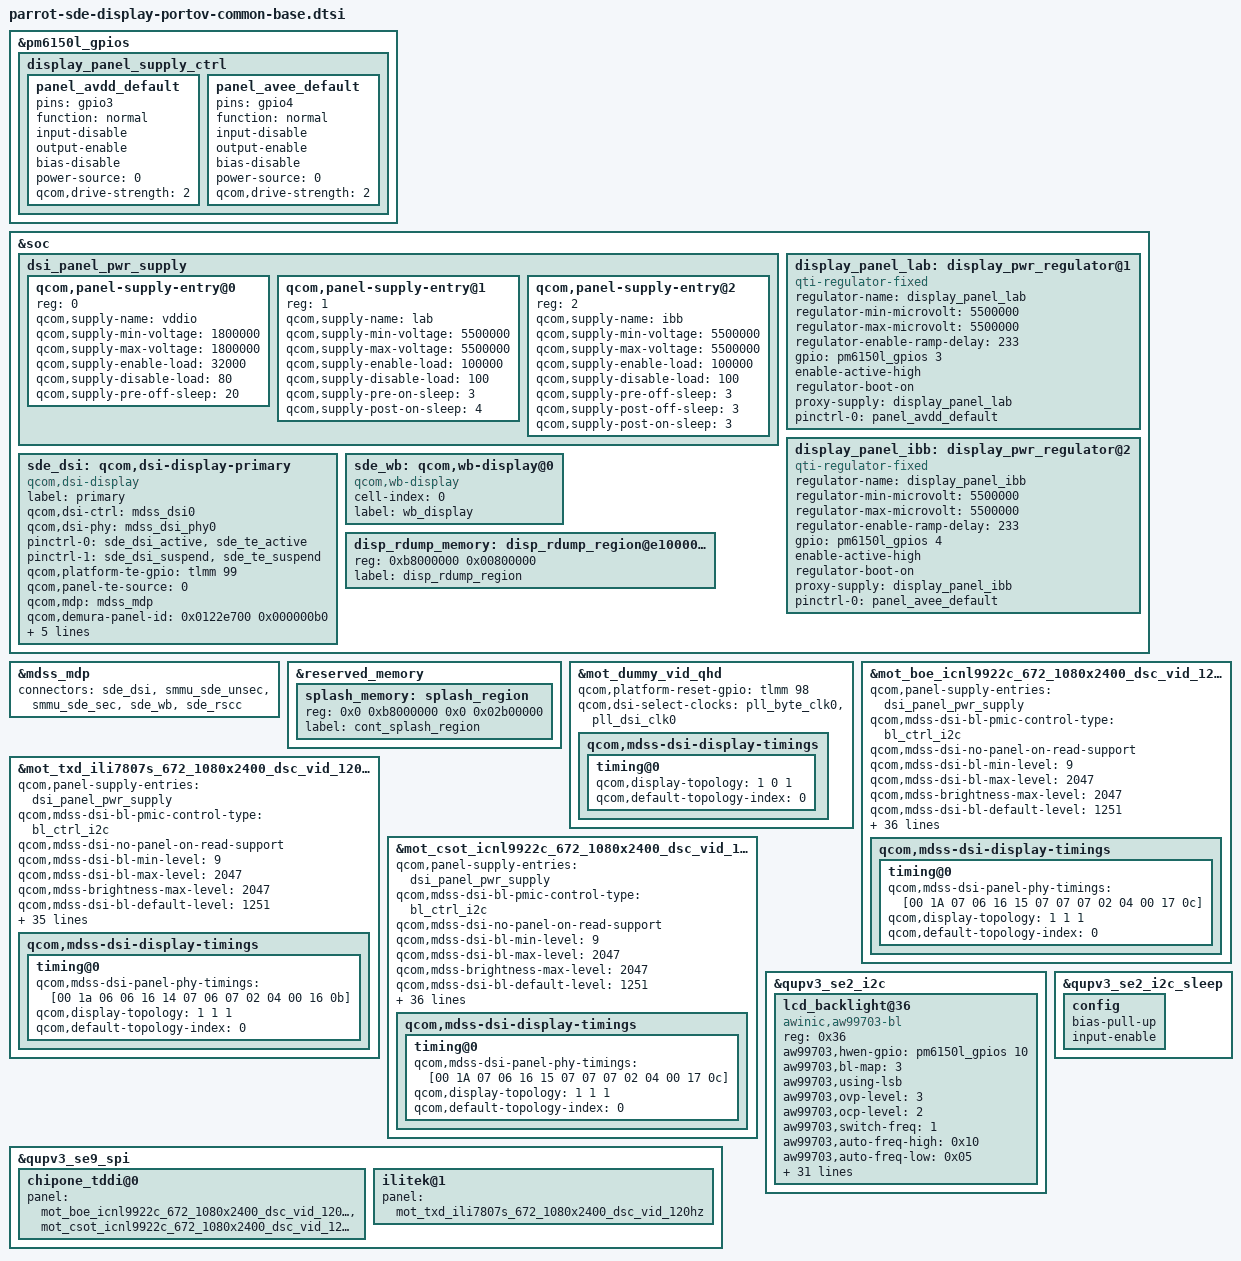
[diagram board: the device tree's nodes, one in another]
/*
   this is original from cape-sde-display-hiphi-common-base.dtsi
*/
#include <dt-bindings/clock/qcom,gcc-parrot.h>
#include <dt-bindings/clock/qcom,rpmh.h>
#include "parrot-sde-display-pinctrl.dtsi"
#include "dsi-panel-mot-dummy-qhd-video.dtsi"
#include <dt-bindings/clock/qcom,dispcc-parrot.h>
#include "dsi-panel-mot-boe-icnl9922c-672-1080x2400-dsc-vid-120hz.dtsi"
#include "dsi-panel-mot-txd-ili7807s-672-1080x2400-dsc-vid-120hz.dtsi"
#include "dsi-panel-mot-csot-icnl9922c-672-1080x2400-dsc-vid-120hz.dtsi"

&pm6150l_gpios {
	display_panel_supply_ctrl {
		panel_avdd_default: panel_avdd_default {
			pins = "gpio3";
			function = "normal";
			input-disable;
			output-enable;
			bias-disable;
			power-source = <0>;
			qcom,drive-strength = <2>;
		};

		panel_avee_default: panel_avee_default {
			pins = "gpio4";
			function = "normal";
			input-disable;
			output-enable;
			bias-disable;
			power-source = <0>;
			qcom,drive-strength = <2>;
		};
	};
};

&soc {
	dsi_panel_pwr_supply: dsi_panel_pwr_supply {
		#address-cells = <1>;
		#size-cells = <0>;
		qcom,panel-supply-entry@0 {
			reg = <0>;
			qcom,supply-name = "vddio";
			qcom,supply-min-voltage = <1800000>;
			qcom,supply-max-voltage = <1800000>;
			qcom,supply-enable-load = <32000>;
			qcom,supply-disable-load = <80>;
			qcom,supply-pre-off-sleep = <20>;
		};

		qcom,panel-supply-entry@1 {
			reg = <1>;
			qcom,supply-name = "lab";
			qcom,supply-min-voltage = <5500000>;
			qcom,supply-max-voltage = <5500000>;
			qcom,supply-enable-load = <100000>;
			qcom,supply-disable-load = <100>;
			qcom,supply-pre-on-sleep = <3>;
			qcom,supply-post-on-sleep = <4>;
		};

		qcom,panel-supply-entry@2 {
			reg = <2>;
			qcom,supply-name = "ibb";
			qcom,supply-min-voltage = <5500000>;
			qcom,supply-max-voltage = <5500000>;
			qcom,supply-enable-load = <100000>;
			qcom,supply-disable-load = <100>;
			qcom,supply-pre-off-sleep = <3>;
			qcom,supply-post-off-sleep = <3>;
			qcom,supply-post-on-sleep = <3>;
		};
	};

	display_panel_lab: display_pwr_regulator@1 {
		compatible = "qti-regulator-fixed";
		regulator-name = "display_panel_lab";
		regulator-min-microvolt = <5500000>;
		regulator-max-microvolt = <5500000>;
		regulator-enable-ramp-delay = <233>;
		gpio = <&pm6150l_gpios 3 0>;
		enable-active-high;
		regulator-boot-on;
		proxy-supply = <&display_panel_lab>;
		pinctrl-names = "default";
		pinctrl-0 = <&panel_avdd_default>;
	};

	display_panel_ibb: display_pwr_regulator@2 {
		compatible = "qti-regulator-fixed";
		regulator-name = "display_panel_ibb";
		regulator-min-microvolt = <5500000>;
		regulator-max-microvolt = <5500000>;
		regulator-enable-ramp-delay = <233>;
		gpio = <&pm6150l_gpios 4 0>;
		enable-active-high;
		regulator-boot-on;
		proxy-supply = <&display_panel_ibb>;
		pinctrl-names = "default";
		pinctrl-0 = <&panel_avee_default>;
	};

	sde_dsi: qcom,dsi-display-primary {
		compatible = "qcom,dsi-display";
		label = "primary";

		qcom,dsi-ctrl = <&mdss_dsi0>;
		qcom,dsi-phy = <&mdss_dsi_phy0>;

		pinctrl-names = "panel_active", "panel_suspend";
		pinctrl-0 = <&sde_dsi_active &sde_te_active>;
		pinctrl-1 = <&sde_dsi_suspend &sde_te_suspend>;

		qcom,platform-te-gpio = <&tlmm 99 0>;
		qcom,panel-te-source = <0>;

		qcom,mdp = <&mdss_mdp>;
		qcom,demura-panel-id = <0x0122e700 0x000000b0>;
	};
};

&soc {
	sde_wb: qcom,wb-display@0 {
		compatible = "qcom,wb-display";
		cell-index = <0>;
		label = "wb_display";
	};

	disp_rdump_memory: disp_rdump_region@e1000000 {
		reg = <0xb8000000 0x00800000>;
		label = "disp_rdump_region";
	};
};

&sde_dsi {
	clocks = <&mdss_dsi_phy0 0>,
			<&mdss_dsi_phy0 1>,
			 /*
			  * Currently the dsi clock handles are under the dsi
			  * controller DT node. As soon as the controller probe
			  * finishes, the dispcc sync state can get called before
			  * the dsi_display probe potentially disturbing the clock
			  * votes for cont_splash use case. Hence we are no longer
			  * protected by the component model in this case against the
			  * disp cc sync state getting triggered after the dsi_ctrl
			  * probe. To protect against this incorrect sync state trigger
			  * add this dummy MDP clk vote handle to the dsi_display
			  * DT node. Since the dsi_display driver does not parse
			  * MDP clock nodes, no actual vote shall be added and this
			  * change is done just to satisfy sync state requirements.
			  */
			 <&dispcc DISP_CC_MDSS_MDP_CLK>;
	clock-names = "pll_byte_clk0", "pll_dsi_clk0",
			"mdp_core_clk";
};

&mdss_mdp {
	connectors = <&sde_dsi &smmu_sde_unsec &smmu_sde_sec &sde_wb &sde_rscc>;
};

&reserved_memory {
	splash_memory: splash_region {
		reg = <0x0 0xb8000000 0x0 0x02b00000>;
		label = "cont_splash_region";
	};
};

&sde_dsi {
	/delete-property/ vddio-supply;
	/delete-property/ vci-supply;
	/delete-property/ lab-supply;
	/delete-property/ ibb-supply;
	/delete-property/ extvdd-supply;

	lab-supply = <&display_panel_lab>;
	ibb-supply = <&display_panel_ibb>;

	qcom,dsi-default-panel = <&mot_dummy_vid_qhd>;
};

&mot_dummy_vid_qhd {
	qcom,platform-reset-gpio = <&tlmm 98 0>;

	qcom,dsi-select-clocks = "pll_byte_clk0", "pll_dsi_clk0";
	qcom,mdss-dsi-display-timings {
		timing@0 {
			qcom,display-topology = <1 0 1>;
			qcom,default-topology-index = <0>;
		};
	};
};

&mot_boe_icnl9922c_672_1080x2400_dsc_vid_120hz {
	qcom,panel-supply-entries = <&dsi_panel_pwr_supply>;
	qcom,mdss-dsi-bl-pmic-control-type = "bl_ctrl_i2c";
	//qcom,mdss-dsi-sec-bl-pmic-control-type = "bl_ctrl_dcs";
	qcom,mdss-dsi-no-panel-on-read-support;
	qcom,mdss-dsi-bl-min-level = <9>;
	qcom,mdss-dsi-bl-max-level = <2047>;
	qcom,mdss-brightness-max-level = <2047>;
	qcom,mdss-dsi-bl-default-level = <1251>;
	qcom,platform-reset-gpio = <&tlmm 98 0>;
	qcom,platform-te-gpio = <&tlmm 99 0>;
	qcom,bl-dsc-cmd-state = "dsi_hs_mode";
	qcom,platform-reset-gpio-always-on;
	qcom,mdss-dsi-bl-inverted-dbv;
	qcom,tp_state_check_enable;
        qcom,deep-standby-need-twice-reset;
        qcom,mdss-dsi-lp11-init;
	qcom,platform-need-execute-shutdown;

	qcom,dsi-select-clocks = "pll_byte_clk0", "pll_dsi_clk0";

	qcom,dsi-supported-dfps-list = <120 90 60 30>;
	qcom,mdss-dsi-pan-enable-dynamic-fps;
	qcom,mdss-dsi-pan-fps-update = "dfps_immediate_porch_mode_vfp";

	qcom,mdss-dsi-cabc-mv-command = [
			39 00 00 40 00 00 04 F0 99 22 0C
			39 00 00 40 02 00 20 E1 0F 1F 2F 3F 4F 5F 6F 7F 90 A0 B0 C0 D0 E0 E8 E7 E7 E7 E7 E9 EB EC ED F0 F0 F3 F6 F9 FD FF FF
			39 00 00 40 02 00 21 E2 2F FF 2F FF 2F FF 2F FF 31 47 32 8F 33 D6 35 1E 36 66 37 EF 39 78 3B 01 3C 8A 3E 14 3F FF 3F FF
			39 00 00 00 02 00 04 F0 00 00 00
			];
	qcom,mdss-dsi-cabc-mv-command-state =  "dsi_hs_mode";
	qcom,mdss-dsi-cabc-ui-command = [
			39 00 00 40 00 00 04 F0 99 22 0C
			39 00 00 40 02 00 20 E1 0F 1F 2F 3F 4F 5F 6F 7F 90 A0 B0 C0 D0 E0 E8 EC ED EF F1 F8 F8 F8 F9 FB FB FC FD FE FF FF FF
			39 00 00 40 02 00 21 E2 36 24 37 4B 38 72 39 99 3D 00 3C 0F 3B C2 3B A5 3C 28 3C ED 3D B1 3E 76 3F 3A 3F FF 3F FF 3F FF
			39 00 00 00 02 00 04 F0 00 00 00
			];
	qcom,mdss-dsi-cabc-ui-command-state =  "dsi_hs_mode";
	qcom,mdss-dsi-cabc-dis-command = [
			39 00 00 40 00 00 04 F0 99 22 0C
			39 00 00 40 02 00 20 E1 0F 1F 2F 3F 4F 5F 6F 7F 90 A0 B0 C0 D0 E0 E8 FF FF FF FF FF FF FF FF FF FF FF FF FF FF FF FF
			39 00 00 40 02 00 21 E2 3F FF 3F FF 3F FF 3F FF 3F FF 3F FF 3F FF 3F FF 3F FF 3F FF 3F FF 3F FF 3F FF 3F FF 3F FF 3F FF
			39 00 00 00 02 00 04 F0 00 00 00
			];
	qcom,mdss-dsi-cabc-dis-command-state =  "dsi_hs_mode";

	qcom,esd-check-enabled;
	qcom,mdss-dsi-panel-status-check-mode = "reg_read";
	qcom,mdss-dsi-panel-status-command = [06 01 00 01 00 00 01 0a];
	qcom,mdss-dsi-panel-status-command-state = "dsi_lp_mode";
	qcom,mdss-dsi-panel-status-value = <0x9c>;
	qcom,mdss-dsi-panel-status-read-length = <1>;

	qcom,mdss-dsi-display-timings {
		timing@0 {
			/*120HZ timing*/
			qcom,mdss-dsi-panel-phy-timings = [00 1A 07 06 16 15 07
				07 07 02 04 00 17 0c];
			qcom,display-topology = <1 1 1>;
			qcom,default-topology-index = <0>;
		};
	};

};

&mot_txd_ili7807s_672_1080x2400_dsc_vid_120hz {
	qcom,panel-supply-entries = <&dsi_panel_pwr_supply>;
	qcom,mdss-dsi-bl-pmic-control-type = "bl_ctrl_i2c";
	//qcom,mdss-dsi-sec-bl-pmic-control-type = "bl_ctrl_dcs";
	qcom,mdss-dsi-no-panel-on-read-support;
	qcom,mdss-dsi-bl-min-level = <9>;
	qcom,mdss-dsi-bl-max-level = <2047>;
	qcom,mdss-brightness-max-level = <2047>;
	qcom,mdss-dsi-bl-default-level = <1251>;
	qcom,platform-reset-gpio = <&tlmm 98 0>;
	qcom,platform-te-gpio = <&tlmm 99 0>;
	qcom,bl-dsc-cmd-state = "dsi_hs_mode";
	qcom,platform-reset-gpio-always-on;
	qcom,mdss-dsi-bl-inverted-dbv;
	qcom,tp_state_check_enable;
	qcom,mdss-dsi-lp11-init;
	qcom,platform-need-execute-shutdown;

	qcom,dsi-select-clocks = "pll_byte_clk0", "pll_dsi_clk0";

	qcom,dsi-supported-dfps-list = <120 90 60 30>;
	qcom,mdss-dsi-pan-enable-dynamic-fps;
	qcom,mdss-dsi-pan-fps-update = "dfps_immediate_porch_mode_vfp";

	qcom,mdss-dsi-cabc-mv-command = [
			39 00 00 40 00 00 04 FF 78 07 00
			39 00 00 00 00 00 02 55 03
			];
	qcom,mdss-dsi-cabc-mv-command-state =  "dsi_hs_mode";
	qcom,mdss-dsi-cabc-ui-command = [
			39 00 00 40 00 00 04 FF 78 07 00
			39 00 00 00 00 00 02 55 01
			];
	qcom,mdss-dsi-cabc-ui-command-state =  "dsi_hs_mode";
	qcom,mdss-dsi-cabc-dis-command = [
			39 00 00 40 00 00 04 FF 78 07 00
			39 00 00 00 00 00 02 55 00
			];
	qcom,mdss-dsi-cabc-dis-command-state =  "dsi_hs_mode";

	qcom,esd-check-enabled;
	qcom,mdss-dsi-panel-status-check-mode = "reg_read";
	qcom,mdss-dsi-panel-status-command = [06 01 00 01 00 00 01 0a];
	qcom,mdss-dsi-panel-status-command-state = "dsi_lp_mode";
	qcom,mdss-dsi-panel-status-value = <0x9c>;
	qcom,mdss-dsi-panel-status-read-length = <1>;

	qcom,mdss-dsi-display-timings {
		timing@0 {
			/*120HZ timing*/
			qcom,mdss-dsi-panel-phy-timings = [00 1a 06 06 16 14 07
				06 07 02 04 00 16 0b];
			qcom,display-topology = <1 1 1>;
			qcom,default-topology-index = <0>;
		};
	};

};

&mot_csot_icnl9922c_672_1080x2400_dsc_vid_120hz {
	qcom,panel-supply-entries = <&dsi_panel_pwr_supply>;
	qcom,mdss-dsi-bl-pmic-control-type = "bl_ctrl_i2c";
	//qcom,mdss-dsi-sec-bl-pmic-control-type = "bl_ctrl_dcs";
	qcom,mdss-dsi-no-panel-on-read-support;
	qcom,mdss-dsi-bl-min-level = <9>;
	qcom,mdss-dsi-bl-max-level = <2047>;
	qcom,mdss-brightness-max-level = <2047>;
	qcom,mdss-dsi-bl-default-level = <1251>;
	qcom,platform-reset-gpio = <&tlmm 98 0>;
	qcom,platform-te-gpio = <&tlmm 99 0>;
	qcom,bl-dsc-cmd-state = "dsi_hs_mode";
	qcom,platform-reset-gpio-always-on;
	qcom,mdss-dsi-bl-inverted-dbv;
	qcom,tp_state_check_enable;
	qcom,deep-standby-need-twice-reset;
	qcom,mdss-dsi-lp11-init;
	qcom,platform-need-execute-shutdown;

	qcom,dsi-select-clocks = "pll_byte_clk0", "pll_dsi_clk0";

	qcom,dsi-supported-dfps-list = <120 90 60 30>;
	qcom,mdss-dsi-pan-enable-dynamic-fps;
	qcom,mdss-dsi-pan-fps-update = "dfps_immediate_porch_mode_vfp";

	qcom,mdss-dsi-cabc-mv-command = [
			39 00 00 40 00 00 04 F0 99 22 0C
			39 00 00 40 02 00 20 E1 0F 1F 2F 3F 4F 5F 6F 7F 90 A0 B0 C0 D0 E0 E8 E7 E7 E7 E7 E9 EB EC ED F0 F0 F3 F6 F9 FD FF FF
			39 00 00 40 02 00 21 E2 2F FF 2F FF 2F FF 2F FF 31 47 32 8F 33 D6 35 1E 36 66 37 EF 39 78 3B 01 3C 8A 3E 14 3F FF 3F FF
			39 00 00 00 02 00 04 F0 00 00 00
			];
	qcom,mdss-dsi-cabc-mv-command-state =  "dsi_hs_mode";
	qcom,mdss-dsi-cabc-ui-command = [
			39 00 00 40 00 00 04 F0 99 22 0C
			39 00 00 40 02 00 20 E1 0F 1F 2F 3F 4F 5F 6F 7F 90 A0 B0 C0 D0 E0 E8 EC ED EF F1 F8 F8 F8 F9 FB FB FC FD FE FF FF FF
			39 00 00 40 02 00 21 E2 36 24 37 4B 38 72 39 99 3D 00 3C 0F 3B C2 3B A5 3C 28 3C ED 3D B1 3E 76 3F 3A 3F FF 3F FF 3F FF
			39 00 00 00 02 00 04 F0 00 00 00
			];
	qcom,mdss-dsi-cabc-ui-command-state =  "dsi_hs_mode";
	qcom,mdss-dsi-cabc-dis-command = [
			39 00 00 40 00 00 04 F0 99 22 0C
			39 00 00 40 02 00 20 E1 0F 1F 2F 3F 4F 5F 6F 7F 90 A0 B0 C0 D0 E0 E8 FF FF FF FF FF FF FF FF FF FF FF FF FF FF FF FF
			39 00 00 40 02 00 21 E2 3F FF 3F FF 3F FF 3F FF 3F FF 3F FF 3F FF 3F FF 3F FF 3F FF 3F FF 3F FF 3F FF 3F FF 3F FF 3F FF
			39 00 00 00 02 00 04 F0 00 00 00
			];
	qcom,mdss-dsi-cabc-dis-command-state =  "dsi_hs_mode";

	qcom,esd-check-enabled;
	qcom,mdss-dsi-panel-status-check-mode = "reg_read";
	qcom,mdss-dsi-panel-status-command = [06 01 00 01 00 00 01 0a];
	qcom,mdss-dsi-panel-status-command-state = "dsi_lp_mode";
	qcom,mdss-dsi-panel-status-value = <0x9c>;
	qcom,mdss-dsi-panel-status-read-length = <1>;

	qcom,mdss-dsi-display-timings {
		timing@0 {
			/*120HZ timing*/
			qcom,mdss-dsi-panel-phy-timings = [00 1A 07 06 16 15 07
				07 07 02 04 00 17 0c];
			qcom,display-topology = <1 1 1>;
			qcom,default-topology-index = <0>;
		};
	};

};

&qupv3_se2_i2c {
	status = "ok";

        lcd_backlight@36 {
                compatible = "awinic,aw99703-bl", "ktd,ktd3136";
                reg = <0x36>;

		/* Awinic, aw99703 */
                aw99703,hwen-gpio = <&pm6150l_gpios 10 0>;
                aw99703,bl-map = <3>; /* brightness map level 1:256,2:1024,3:2048 */
                aw99703,using-lsb;
                aw99703,ovp-level = <3>; /* 0:17.5V, 1:24V, 2:31V, 3:38V, 4:41.5V */
                aw99703,ocp-level = <2>; /* 0:0.9A, 1:1.8A, 2:2.7A, 3:3.4A */
                aw99703,switch-freq = <1>; /* 1000kHz(default) */
                aw99703,auto-freq-high = <0x10>;
                aw99703,auto-freq-low = <0x05>;
                aw99703,bl-fscal-led = <0x1E>; /* 28.8mA */
                aw99703,bl-channel = <3>; /* 3 led string */
                aw99703,turn-on-ramp = <0x00>; /* 512us */
                aw99703,turn-off-ramp = <0x04>; /* 8ms */
                aw99703,pwm-trans-dim = <0>; /* 2ms */
                aw99703,i2c-trans-dim = <1>; /* 128ms */
                aw99703,skip-first-trans;
                aw99703,reset-trans-delay;
                aw99703,pwm-mode = <1>; /* 1 pwm enable,0 PWM disable */
                aw99703,map-type = <0>; /* 0 exponential, 4 linear */
		current-align-type = <0x03>; /* 0-none,  1-450nit,  2-1000nit,  3-gamma1.5 1000nit */
                aw99703,work-mode = <1>; /* backlight */
		aw99703,default-brightness = <1251>;

		/* ktd3136*/
		ktd,hwen-gpio = <&pm6150l_gpios 10 0>;
                ktd,using-lsb;
                ktd,pwm-frequency = <1>; /* 1MHZ */
                ktd,bl-fscal-led = <0xF1>; /* 29mA */
                ktd,turn-on-ramp = <0x00>;
                ktd,turn-off-ramp = <0x04>;
                ktd,pwm-trans-dim = <0>;
                ktd,i2c-trans-dim = <128>;
                ktd,skip-first-trans;
                ktd,reset-trans-delay;
                ktd,bl-channel = <3>;
                ktd,ovp-level = <32>;  /*25.9v or 32v */
                ktd,ocp-level = <2600>;
                ktd,switching-frequency = <1>;
                ktd,inductor-current = <1>;
                ktd,default-brightness = <1251>;
                ktd,map-type = <0>; /* 0 exponential, 1 linear */
                ktd,current-align-type = <0x03>;  /* 0-none,  1-450nit,  2-1000nit,  3-gamma1.5 1000nit */
	};
};

&qupv3_se2_i2c_sleep {
    config {
        /delete-property/ bias-disable;
        bias-pull-up;
        input-enable;
    };
};

&qupv3_se9_spi {
	chipone_tddi@0{
		panel = <&mot_boe_icnl9922c_672_1080x2400_dsc_vid_120hz
			 &mot_csot_icnl9922c_672_1080x2400_dsc_vid_120hz>;
	};
	ilitek@1{
		panel = <&mot_txd_ili7807s_672_1080x2400_dsc_vid_120hz>;
	};
};
